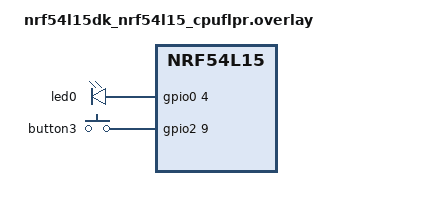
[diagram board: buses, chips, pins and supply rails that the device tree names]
/*
 * Copyright (c) 2026 Nordic Semiconductor ASA
 *
 * SPDX-License-Identifier: LicenseRef-Nordic-5-Clause
 */

&led0 {
	gpios = <&gpio0 4 GPIO_ACTIVE_HIGH>;
};

&button3 {
	gpios = <&gpio2 9 GPIO_ACTIVE_HIGH>;
};

&uart30 {
	zephyr,pm-device-runtime-auto;
	disable-rx;
};
